# EFR32BG26B511F3200IM68 register map
Vendor: Silicon Labs; Series: EFR32; File version: B
Registers are 32-bit, read-write, reset 0x0 unless marked. A register's access mark holds for its fields unless they carry their own. Offsets are from the block's base; [hi:lo] are bit positions; {n}, {i} and the like mark numbered series.

## SYSCFG_NS — SYSCFG_NS Registers
Base 0x50080000
Same registers: SYSCFG_S 0x40080000
0x04 IPVERSION ro reset 0x9
  [31:0] IPVERSION — New BitField
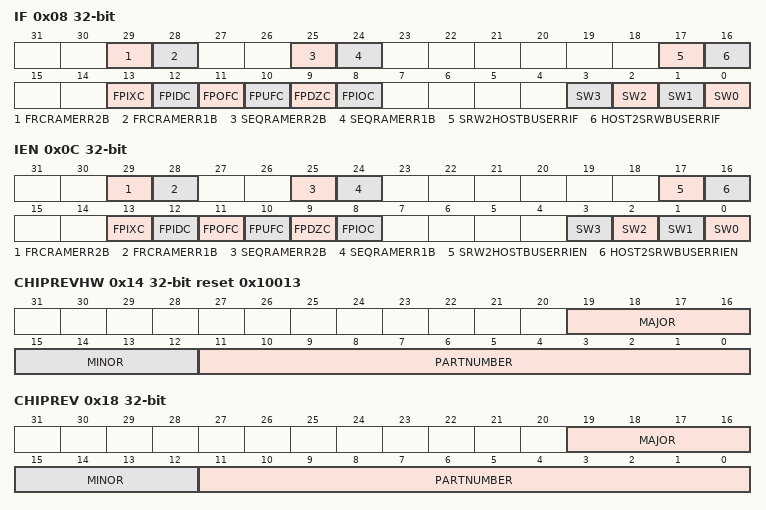
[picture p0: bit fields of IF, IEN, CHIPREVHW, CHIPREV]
0x08 IF — Read to get system status.
  [29] FRCRAMERR2B — FRCRAM Error 2-bit Interrupt Flag
  [28] FRCRAMERR1B — FRCRAM Error 1-bit Interrupt Flag
  [25] SEQRAMERR2B — SEQRAM Error 2-bit Interrupt Flag
  [24] SEQRAMERR1B — SEQRAM Error 1-bit Interrupt Flag
  [17] SRW2HOSTBUSERRIF — SRW2HOSTBUSERRIF Interrupt Flag
  [16] HOST2SRWBUSERRIF — HOST2SRWBUSERRIF Interrupt Flag
  [13] FPIXC — FPU Inexact interrupt flag
  [12] FPIDC — FPU Input denormal interrupt flag
  [11] FPOFC — FPU Overflow interrupt flag
  [10] FPUFC — FPU Underflow interrupt flag
  [9] FPDZC — FPU Divide by zero interrupt flag
  [8] FPIOC — FPU Invalid Operation interrupt flag
  [n] SW{n} (n=0..3) — Software Interrupt Flag
0x0C IEN — Write to enable interrupts.
  [29] FRCRAMERR2B — FRCRAM Error 2-bit Interrupt Enable
  [28] FRCRAMERR1B — FRCRAM Error 1-bit Interrupt Enable
  [25] SEQRAMERR2B — SEQRAM Error 2-bit Interrupt Enable
  [24] SEQRAMERR1B — SEQRAM Error 1-bit Interrupt Enable
  [17] SRW2HOSTBUSERRIEN — SRW2HOSTBUSERRIEN Interrupt Enable
  [16] HOST2SRWBUSERRIEN — HOST2SRWBUSERRIEN Interrupt Enable
  [13] FPIXC — FPU Inexact Interrupt Enable
  [12] FPIDC — FPU Input denormal Interrupt Enable
  [11] FPOFC — FPU Overflow Interrupt Enable
  [10] FPUFC — FPU Underflow Interrupt Enable
  [9] FPDZC — FPU Divide by zero Interrupt Enable
  [8] FPIOC — FPU Invalid Operation Interrupt Enable
  [n] SW{n} (n=0..3) — Software Interrupt Enable
0x14 CHIPREVHW reset 0x10013 — Read to get the hard-wired chip revision.
  [19:16] MAJOR ro — Hardwired Chip Major value
  [15:12] MINOR ro — Hardwired Chip Minor value
  [11:0] PARTNUMBER — Hardwired Chip Part Number value
0x18 CHIPREV — Read to get the chip revision programmed by feature configuration.
  [19:16] MAJOR — Chip Revision Major value
  [15:12] MINOR — Chip Revision Minor value
  [11:0] PARTNUMBER — Chip Part Number value
0x24 CFGSYSTIC — Configure the source of the system tick for the M33.
  [0] SYSTICEXTCLKEN — SysTick External Clock Enable
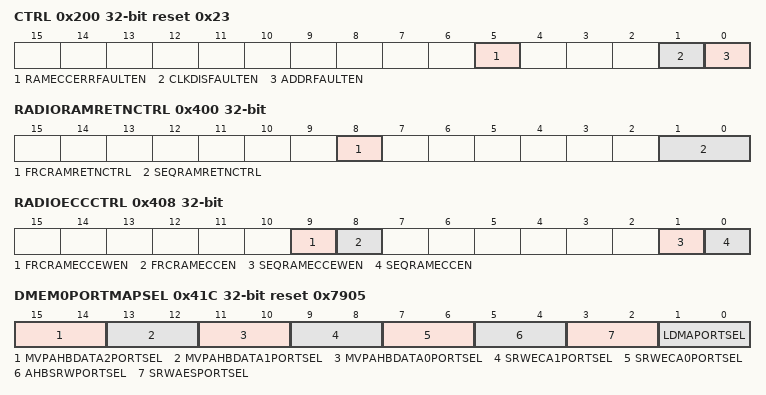
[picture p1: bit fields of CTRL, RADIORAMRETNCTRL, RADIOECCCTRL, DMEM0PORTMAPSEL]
0x200 CTRL reset 0x23 — Configure to provide general RAM configuration.
  [5] RAMECCERRFAULTEN — Two bit ECC error bus fault response ena
  [1] CLKDISFAULTEN — Disabled Clkbus Bus Fault Enable
  [0] ADDRFAULTEN — Invalid Address Bus Fault Response Enabl
0x208 DMEM0RETNCTRL — Configure to provide general RAM retention configuration.
  [31:0] RAMRETNCTRL — DMEM0 blockset retention control
    0=ALLON (None of the RAM blocks powered down); 0x80000000=BLK31 (Power down RAM block 31 (address range 0x2007C000-0x20080000)); 0xC0000000=BLK30TO31 (Power down RAM blocks 30 and above (address range 0x20078000-0x20080000)); 0xE0000000=BLK29TO31 (Power down RAM blocks 29 and above (address range 0x20074000-0x20080000)); 0xF0000000=BLK28TO31 (Power down RAM blocks 28 and above (address range 0x20070000-0x20080000)); 0xF8000000=BLK27TO31 (Power down RAM blocks 27 and above (address range 0x2006C000-0x20080000)); 0xFC000000=BLK26TO31 (Power down RAM blocks 26 and above (address range 0x20068000-0x20080000)); 0xFE000000=BLK25TO31 (Power down RAM blocks 25 and above (address range 0x20064000-0x20080000)); 0xFF000000=BLK24TO31 (Power down RAM blocks 24 and above (address range 0x20060000-0x20080000)); 0xFF800000=BLK23TO31 (Power down RAM blocks 23 and above (address range 0x2005C000-0x20080000)); 0xFFC00000=BLK22TO31 (Power down RAM blocks 22 and above (address range 0x20058000-0x20080000)); 0xFFE00000=BLK21TO31 (Power down RAM blocks 21 and above (address range 0x20054000-0x20080000)); 0xFFF00000=BLK20TO31 (Power down RAM blocks 20 and above (address range 0x20050000-0x20080000)); 0xFFF80000=BLK19TO31 (Power down RAM blocks 19 and above (address range 0x2004C000-0x20080000)); 0xFFFC0000=BLK18TO31 (Power down RAM blocks 18 and above (address range 0x20048000-0x20080000)); 0xFFFE0000=BLK17TO31 (Power down RAM blocks 17 and above (address range 0x20044000-0x20080000)); 0xFFFF0000=BLK16TO31 (Power down RAM blocks 16 and above (address range 0x20040000-0x20080000)); 0xFFFF8000=BLK15TO31 (Power down RAM blocks 15 and above (address range 0x2003C000-0x20080000)); 0xFFFFC000=BLK14TO31 (Power down RAM blocks 14 and above (address range 0x20038000-0x20080000)); 0xFFFFE000=BLK13TO31 (Power down RAM blocks 13 and above (address range 0x20034000-0x20080000)); 0xFFFFF000=BLK12TO31 (Power down RAM blocks 12 and above (address range 0x20030000-0x20080000)); 0xFFFFF800=BLK11TO31 (Power down RAM blocks 11 and above (address range 0x2002C000-0x20080000)); 0xFFFFFC00=BLK10TO31 (Power down RAM blocks 10 and above (address range 0x20028000-0x20080000)); 0xFFFFFE00=BLK9TO31 (Power down RAM blocks 9 and above (address range 0x20024000-0x20080000)); 0xFFFFFF00=BLK8TO31 (Power down RAM blocks 8 and above (address range 0x20020000-0x20080000)); 0xFFFFFF80=BLK7TO31 (Power down RAM blocks 7 and above (address range 0x2001c000-0x20080000)); 0xFFFFFFC0=BLK6TO31 (Power down RAM blocks 6 and above (address range 0x20018000-0x20080000)); 0xFFFFFFE0=BLK5TO31 (Power down RAM blocks 5 and above (address range 0x20014000-0x20080000)); 0xFFFFFFF0=BLK4TO31 (Power down RAM blocks 4 and above (address range 0x20010000-0x20080000)); 0xFFFFFFF8=BLK3TO31 (Power down RAM blocks 3 and above (address range 0x2000c000-0x20080000)); 0xFFFFFFFC=BLK2TO31 (Power down RAM blocks 2 and above (address range 0x20008000-0x20080000)); 0xFFFFFFFE=BLK1TO31 (Power down RAM blocks 1 and above (address range 0x20004000-0x20080000)); 0xFFFFFFFF=ALLOFF (All of the RAM blocks are powered down)
0x30C RAMBIASCONF reset 0x2 — Configure RAM bias configure bits.
  [3:0] RAMBIASCTRL — RAM Bias Control
    0=No (None); 1=VSB100 (Voltage Source Bias 100mV); 2=VSB200 (Voltage Source Bias 200mV); 4=VSB300 (Voltage Source Bias 300mV); 8=VSB400 (Voltage Source Bias 400mV)
0x400 RADIORAMRETNCTRL — Configure SEQRAM Retention controls.
  [8] FRCRAMRETNCTRL — FRCRAM Retention Control
    0=ALLON (FRCRAM not powered down); 1=ALLOFF (Power down FRCRAM)
  [1:0] SEQRAMRETNCTRL — SEQRAM Retention Control
    0=ALLON (SEQRAM not powered down); 1=BLK0 (Power down SEQRAM block 0); 2=BLK1 (Power down SEQRAM block 1); 3=ALLOFF (Power down all SEQRAM blocks)
0x408 RADIOECCCTRL — Configure to set RAM ECC control.
  [9] FRCRAMECCEWEN — FRCRAM ECC Error Writeback Enable
  [8] FRCRAMECCEN — FRCRAM ECC Enable
  [1] SEQRAMECCEWEN — SEQRAM ECC Error Writeback Enable
  [0] SEQRAMECCEN — SEQRAM ECC Enable
0x410 SEQRAMECCADDR ro — Read to get status of the SEQRAM ECC error address.
  [31:0] SEQRAMECCADDR — SEQRAM ECC Address
0x414 FRCRAMECCADDR ro — Read to get status of the FRCRAM ECC error address.
  [31:0] FRCRAMECCADDR — FRCRAM ECC Error Address
0x418 ICACHERAMRETNCTRL — Configure Host ICACHERAM retention configuration.
  [0] RAMRETNCTRL — ICACHERAM Retention control
    0=ALLON (None of the Host ICACHE RAM blocks powered down); 1=ALLOFF (Power down all Host ICACHE RAM blocks)
0x41C DMEM0PORTMAPSEL reset 0x7905 — Configure DMEM0 port remap selection.
  [15:14] MVPAHBDATA2PORTSEL — MVPAHBDATA2 portmap selection
  [13:12] MVPAHBDATA1PORTSEL — MVPAHBDATA1 portmap selection
  [11:10] MVPAHBDATA0PORTSEL — MVPAHBDATA0 portmap selection
  [9:8] SRWECA1PORTSEL — SRWECA1 portmap selection
  [7:6] SRWECA0PORTSEL — SRWECA0 portmap selection
  [5:4] AHBSRWPORTSEL — AHBSRW portmap selection
  [3:2] SRWAESPORTSEL — SRWAES portmap selection
  [1:0] LDMAPORTSEL — LDMA portmap selection
0x600 ROOTDATA0 — Generic data space for user to pass to root, e.g., address of struct in mem
  [31:0] DATA
0x604 ROOTDATA1 — Generic data space for user to pass to root, e.g., address of struct in mem
  [31:0] DATA
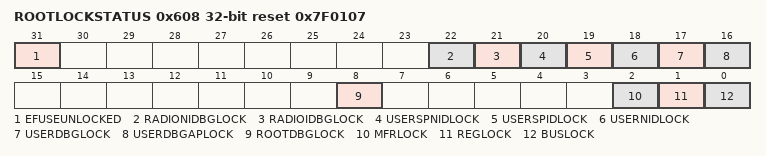
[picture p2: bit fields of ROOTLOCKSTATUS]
0x608 ROOTLOCKSTATUS ro reset 0x7F0107 — This register returns the status of the SE managed locks.
  [31] EFUSEUNLOCKED
  [22] RADIONIDBGLOCK — Radio Non-invasive Debug Lock
  [21] RADIOIDBGLOCK — Radio Invasive Debug Lock
  [20] USERSPNIDLOCK — User Secure Non-invasive Debug Lock
  [19] USERSPIDLOCK — User Secure Invasive Debug Lock
  [18] USERNIDLOCK — User Non-invasive Debug Lock
  [17] USERDBGLOCK — User Invasive Debug Lock
  [16] USERDBGAPLOCK — User Debug Access Port Lock
  [8] ROOTDBGLOCK — Root Debug Lock
  [2] MFRLOCK — Manufacture Lock
  [1] REGLOCK — Register Lock
  [0] BUSLOCK
0x60C ROOTSESWVERSION — SE Software version
  [31:0] SWVERSION
